AUTOSAR XML (schema 00044)
package /E40_Platform_System_SystemPackage/Components
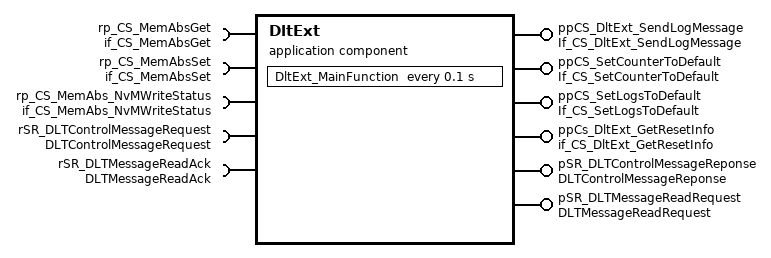
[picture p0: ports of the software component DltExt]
  application sw component type DltExt
    provide port ppCS_DltExt_SendLogMessage: server-com-spec{operation=SendLogMessage, queue-length=1}, provided-interface=If_CS_DltExt_SendLogMessage
    provide port ppCS_SetCounterToDefault: server-com-spec{operation=SetCounterToDefault, queue-length=1}, provided-interface=If_CS_SetCounterToDefault
    provide port ppCS_SetLogsToDefault: server-com-spec{operation=SetLogsToDefault, queue-length=1}, provided-interface=If_CS_SetLogsToDefault
    require port rp_CS_MemAbsGet: required-interface=if_CS_MemAbsGet
      required-com-specs:
        Get_BsConst_Audio_Element
        Get_BsConst_Communication_Element
        Get_BsConst_EngOffTimer_Element
        Get_BsConst_FuelGauge_Element
        Get_BsConst_OilGauge_Element
        Get_BsConst_PowerGauge_Element
        Get_BsConst_Power_Element
        Get_BsConst_RealTimeClock_Element
        Get_BsConst_ServiceReminder_Element
        Get_BsConst_SpeedoGauge_Element
        Get_BsConst_TachoGauge_Element
        Get_BsConst_TempGauge_Element
        Get_BsConst_TripComputer_Element
        Get_BsConst_Warning_Element
        Get_BsCys_Certicificate_Element
        Get_BsDiag_Dtc_Element
        Get_BsDiag_ErrorRecord_Element
        Get_BsReten_Audio_Element
        Get_BsReten_Communication_Element
        Get_BsReten_Display_Element
        Get_BsReten_Gauges_Element
        Get_BsReten_Illumination_Element
        Get_BsReten_Odometer_Element
        Get_BsReten_Personalization_Element
        Get_BsReten_Power_Element
        Get_BsReten_RealTimeClock_Element
        Get_BsReten_Tripcomputer_Element
        Get_BsReten_Warning_Element
        Get_BsRt_CusDlt_Element
        Get_BsRt_FuelGauge_Element
        Get_BsRt_Illumination_Element
        Get_BsRt_Odometer_Element
        Get_BsRt_OilGauge_Element
        Get_BsRt_Personalization_Element
        Get_BsRt_PowerGauge_Element
        Get_BsRt_RealTimeClock_Element
        Get_BsRt_SpeedoGauge_Element
        Get_BsRt_TachoGauge_Element
        Get_BsRt_TempGauge_Element
        Get_BsRt_TripComputer_Element
        Get_BsRt_Warning_Element
        Get_BsShare_EcuPartNumber_Element
        Get_BsShare_SwUpdFotaFinPrint_Element
        Get_BsShare_SwUpdFotaMode_Element
        Get_BsShare_SwUpdFotaStatus_Element
        Get_BsShare_SwUpdFotadecrypt_Element
        Get_BsShare_SwUpdReflash_Element
        Get_BsShare_VehicleConfig_Element
        Get_BsShare_VisMeet_Element
        Get_RefCys_Certicificate1_Element
        Get_RefCys_Certicificate_Element
        Get_BsShare_VisteonPartNumber
        Get_BsShare_VisteonPCBPartNumber
        Get_BsShare_SMTPlantNumber
        Get_BsShare_SMTManufacturingDate
        Get_BsShare_ProductSerialNumber
        Get_BsShare_PCBSerialNumber
        Get_BsShare_HWModification
        Get_BsShare_AssemblyPlantNumber
        Get_BsShare_AssemblyManufacturingDate
        Get_BsShare_VisMeet_EOLEntry_Element
        Get_BsConst_Temperature_Sensor_Conv_SafeCopy2
        Get_BsConst_Temperature_Sensor_Conv_SafeCopy1
        Get_BsConst_Temperature_Sensor_Conv
        Get_BsConst_Temp_Threshold_Hysteresis_Derating_SafeCopy2
        Get_BsConst_Temp_Threshold_Hysteresis_Derating_SafeCopy1
        Get_BsConst_Temp_Threshold_Hysteresis_Derating
        Get_BsConst_PWM_boost_bypass_duty_SafeCopy2
        Get_BsConst_PWM_boost_bypass_duty_SafeCopy1
        Get_BsConst_PWM_boost_bypass_duty
        Get_BsConst_PCB_Temperature_Sensor_Conv_SafeCopy2
        Get_BsConst_PCB_Temperature_Sensor_Conv_SafeCopy1
        Get_BsConst_PCB_Temperature_Sensor_Conv
        Get_BsConst_Lookup_Curve_HotSpot_Coef_Y_SafeCopy2
        Get_BsConst_Lookup_Curve_HotSpot_Coef_Y_SafeCopy1
        Get_BsConst_Lookup_Curve_HotSpot_Coef_Y
        Get_BsConst_Lookup_Curve_HotSpot_Coef_X_SafeCopy2
        Get_BsConst_Lookup_Curve_HotSpot_Coef_X_SafeCopy1
        Get_BsConst_Lookup_Curve_HotSpot_Coef_X
        Get_BsConst_Display_Illum_Max_Level_SafeCopy2
        Get_BsConst_Display_Illum_Max_Level_SafeCopy1
        Get_BsConst_Display_Illum_Max_Level
        Get_BsConst_Derating_Backlight_Disable_SafeCopy2
        Get_BsConst_Derating_Backlight_Disable_SafeCopy1
        Get_BsConst_Derating_Backlight_Disable
        Get_BsConst_Compensation_Line_Slope_m_SafeCopy2
        Get_BsConst_Compensation_Line_Slope_m_SafeCopy1
        Get_BsConst_Compensation_Line_Slope_m
        Get_BsConst_Compensation_Line_Shift_b_SafeCopy2
        Get_BsConst_Compensation_Line_Shift_b_SafeCopy1
        Get_BsConst_Compensation_Line_Shift_b
        Get_BsConst_BsConst_Illumination_ReservedByte_SafeCopy2
        Get_BsConst_BsConst_Illumination_ReservedByte_SafeCopy1
        Get_BsConst_BsConst_Illumination_ReservedByte
    require port rp_CS_MemAbsSet: required-interface=if_CS_MemAbsSet
      required-com-specs:
        Set_BsConst_Audio_Element
        Set_BsConst_Communication_Element
        Set_BsConst_EngOffTimer_Element
        Set_BsConst_FuelGauge_Element
        Set_BsConst_OilGauge_Element
        Set_BsConst_PowerGauge_Element
        Set_BsConst_Power_Element
        Set_BsConst_RealTimeClock_Element
        Set_BsConst_ServiceReminder_Element
        Set_BsConst_SpeedoGauge_Element
        Set_BsConst_TachoGauge_Element
        Set_BsConst_TempGauge_Element
        Set_BsConst_TripComputer_Element
        Set_BsConst_Warning_Element
        Set_BsCys_Certicificate_Element
        Set_BsDiag_Dtc_Element
        Set_BsDiag_ErrorRecord_Element
        Set_BsReten_Audio_Element
        Set_BsReten_Communication_Element
        Set_BsReten_Display_Element
        Set_BsReten_Gauges_Element
        Set_BsReten_Illumination_Element
        Set_BsReten_Odometer_Element
        Set_BsReten_Personalization_Element
        Set_BsReten_Power_Element
        Set_BsReten_RealTimeClock_Element
        Set_BsReten_Tripcomputer_Element
        Set_BsReten_Warning_Element
        Set_BsRt_CusDlt_Element
        Set_BsRt_FuelGauge_Element
        Set_BsRt_Illumination_Element
        Set_BsRt_Odometer_Element
        Set_BsRt_OilGauge_Element
        Set_BsRt_Personalization_Element
        Set_BsRt_PowerGauge_Element
        Set_BsRt_RealTimeClock_Element
        Set_BsRt_SpeedoGauge_Element
        Set_BsRt_TachoGauge_Element
        Set_BsRt_TempGauge_Element
        Set_BsRt_TripComputer_Element
        Set_BsRt_Warning_Element
        Set_BsShare_EcuPartNumber_Element
        Set_BsShare_SwUpdFotaFinPrint_Element
        Set_BsShare_SwUpdFotaMode_Element
        Set_BsShare_SwUpdFotaStatus_Element
        Set_BsShare_SwUpdFotadecrypt_Element
        Set_BsShare_SwUpdReflash_Element
        Set_BsShare_VehicleConfig_Element
        Set_BsShare_VisMeet_Element
        Set_RefCys_Certicificate1_Element
        Set_RefCys_Certicificate_Element
        Set_BsShare_VisteonPartNumber
        Set_BsShare_VisteonPCBPartNumber
        Set_BsShare_SMTPlantNumber
        Set_BsShare_SMTManufacturingDate
        Set_BsShare_ProductSerialNumber
        Set_BsShare_PCBSerialNumber
        Set_BsShare_HWModification
        Set_BsShare_AssemblyPlantNumber
        Set_BsShare_AssemblyManufacturingDate
        Set_BsShare_VisMeet_EOLEntry_Element
        Set_BsConst_Temperature_Sensor_Conv_SafeCopy2
        Set_BsConst_Temperature_Sensor_Conv_SafeCopy1
        Set_BsConst_Temperature_Sensor_Conv
        Set_BsConst_Temp_Threshold_Hysteresis_Derating_SafeCopy2
        Set_BsConst_Temp_Threshold_Hysteresis_Derating_SafeCopy1
        Set_BsConst_Temp_Threshold_Hysteresis_Derating
        Set_BsConst_PWM_boost_bypass_duty_SafeCopy2
        Set_BsConst_PWM_boost_bypass_duty_SafeCopy1
        Set_BsConst_PWM_boost_bypass_duty
        Set_BsConst_PCB_Temperature_Sensor_Conv_SafeCopy2
        Set_BsConst_PCB_Temperature_Sensor_Conv_SafeCopy1
        Set_BsConst_PCB_Temperature_Sensor_Conv
        Set_BsConst_Lookup_Curve_HotSpot_Coef_Y_SafeCopy2
        Set_BsConst_Lookup_Curve_HotSpot_Coef_Y_SafeCopy1
        Set_BsConst_Lookup_Curve_HotSpot_Coef_Y
        Set_BsConst_Lookup_Curve_HotSpot_Coef_X_SafeCopy2
        Set_BsConst_Lookup_Curve_HotSpot_Coef_X_SafeCopy1
        Set_BsConst_Lookup_Curve_HotSpot_Coef_X
        Set_BsConst_Display_Illum_Max_Level_SafeCopy2
        Set_BsConst_Display_Illum_Max_Level_SafeCopy1
        Set_BsConst_Display_Illum_Max_Level
        Set_BsConst_Derating_Backlight_Disable_SafeCopy2
        Set_BsConst_Derating_Backlight_Disable_SafeCopy1
        Set_BsConst_Derating_Backlight_Disable
        Set_BsConst_Compensation_Line_Slope_m_SafeCopy2
        Set_BsConst_Compensation_Line_Slope_m_SafeCopy1
        Set_BsConst_Compensation_Line_Slope_m
        Set_BsConst_Compensation_Line_Shift_b_SafeCopy2
        Set_BsConst_Compensation_Line_Shift_b_SafeCopy1
        Set_BsConst_Compensation_Line_Shift_b
        Set_BsConst_BsConst_Illumination_ReservedByte_SafeCopy2
        Set_BsConst_BsConst_Illumination_ReservedByte_SafeCopy1
        Set_BsConst_BsConst_Illumination_ReservedByte
    require port rp_CS_MemAbs_NvMWriteStatus: client-com-spec=NvmWriteStatus, required-interface=if_CS_MemAbs_NvMWriteStatus
    provide port ppCs_DltExt_GetResetInfo: server-com-spec{operation=GetResetInfo, queue-length=1}, provided-interface=if_CS_DltExt_GetResetInfo
    provide port pSR_DLTControlMessageReponse: nonqueued-sender-com-spec{data-element=DLTControlMessageReponseData, init-value=constant-reference=DltExtDLTControlMessageReponseDataValue0}, provided-interface=DLTControlMessageReponse
    provide port pSR_DLTMessageReadRequest: nonqueued-sender-com-spec{data-element=DLTMessageReadRequestData, init-value=constant-reference=DltExtDLTMessageReadRequestDataValue0}, provided-interface=DLTMessageReadRequest
    require port rSR_DLTControlMessageRequest: nonqueued-receiver-com-spec{data-element=DLTControlMessageRequestData, init-value=constant-reference=DltExtDLTControlMessageRequestDataValue0}, required-interface=DLTControlMessageRequest
    require port rSR_DLTMessageReadAck: nonqueued-receiver-com-spec{data-element=DLTMessageReadAckData, init-value=constant-reference=DltExtDLTMessageReadAckDataValue0}, required-interface=DLTMessageReadAck
    behavior IB_DltExt
      timing event TEDltExt_MainFunction: start-on-event=DltExt_MainFunction, period=0.1
      4 x operation invoked event:
        OIE_ppCS_DltExt_SendLogMessage_DltExt_SendLogMessageTrigBySendLogMessage: start-on-event=DltExt_SendLogMessage, operation=ppCS_DltExt_SendLogMessage.SendLogMessage
        OIE_ppCS_SetCounterToDefault_DltExt_SetCounterToDefaultTrigBySetCounterToDefault: start-on-event=DltExt_SetCounterToDefault, operation=ppCS_SetCounterToDefault.SetCounterToDefault
        OIE_ppCS_SetLogsToDefault_DltExt_SetLogsToDefaultTrigBySetLogsToDefault: start-on-event=DltExt_SetLogsToDefault, operation=ppCS_SetLogsToDefault.SetLogsToDefault
        OIE_ppCs_DltExt_GetResetInfo_DltExt_GetResetInfoTrigByGetResetInfo: start-on-event=DltExt_GetResetInfo, operation=ppCs_DltExt_GetResetInfo.GetResetInfo
      data received event DREDltExt_OnDreDLTMessageReadAckDataTrigByDLTMessageReadAckData: start-on-event=DltExt_OnDreDLTMessageReadAckData, data=rSR_DLTMessageReadAck.DLTMessageReadAckData
      port-api-options:
        enable-take-address=false, indirect-api=false, port=ppCS_DltExt_SendLogMessage
        enable-take-address=false, indirect-api=false, port=ppCS_SetCounterToDefault
        enable-take-address=false, indirect-api=false, port=ppCS_SetLogsToDefault
        enable-take-address=false, indirect-api=false, port=rp_CS_MemAbsGet
        enable-take-address=false, indirect-api=false, port=rp_CS_MemAbsSet
        enable-take-address=false, indirect-api=false, port=rp_CS_MemAbs_NvMWriteStatus
        enable-take-address=false, indirect-api=false, port=ppCs_DltExt_GetResetInfo
        enable-take-address=false, indirect-api=false, port=pSR_DLTControlMessageReponse
        enable-take-address=false, indirect-api=false, port=pSR_DLTMessageReadRequest
        enable-take-address=false, indirect-api=false, port=rSR_DLTControlMessageRequest
        enable-take-address=false, indirect-api=false, port=rSR_DLTMessageReadAck
      6 x runnable, all with can-be-invoked-concurrently=true:
        DltExt_MainFunction
          data-receive-point-by-arguments:
            access DRA_rSR_DLTControlMessageRequest_DLTControlMessageRequestData: accessed-variable=rSR_DLTControlMessageRequest.DLTControlMessageRequestData
            access DRA_rSR_DLTMessageReadAck_DLTMessageReadAckData: accessed-variable=rSR_DLTMessageReadAck.DLTMessageReadAckData
          data-send-points:
            access DWA_pSR_DLTControlMessageReponse_DLTControlMessageReponseData: accessed-variable=pSR_DLTControlMessageReponse.DLTControlMessageReponseData
            access DWA_pSR_DLTMessageReadRequest_DLTMessageReadRequestData: accessed-variable=pSR_DLTMessageReadRequest.DLTMessageReadRequestData
          189 x sync call:
            OA_rp_CS_MemAbsGet_Get_BsShare_SwUpdReflash_Element: operation=rp_CS_MemAbsGet.Get_BsShare_SwUpdReflash_Element
            OA_rp_CS_MemAbsGet_Get_BsShare_SwUpdFotaMode_Element: operation=rp_CS_MemAbsGet.Get_BsShare_SwUpdFotaMode_Element
            OA_rp_CS_MemAbsGet_Get_BsShare_SwUpdFotaFinPrint_Element: operation=rp_CS_MemAbsGet.Get_BsShare_SwUpdFotaFinPrint_Element
            OA_rp_CS_MemAbsGet_Get_BsShare_SwUpdFotaStatus_Element: operation=rp_CS_MemAbsGet.Get_BsShare_SwUpdFotaStatus_Element
            OA_rp_CS_MemAbsGet_Get_BsShare_SwUpdFotadecrypt_Element: operation=rp_CS_MemAbsGet.Get_BsShare_SwUpdFotadecrypt_Element
            OA_rp_CS_MemAbsGet_Get_BsShare_EcuPartNumber_Element: operation=rp_CS_MemAbsGet.Get_BsShare_EcuPartNumber_Element
            OA_rp_CS_MemAbsGet_Get_BsShare_VisMeet_Element: operation=rp_CS_MemAbsGet.Get_BsShare_VisMeet_Element
            OA_rp_CS_MemAbsGet_Get_BsShare_VehicleConfig_Element: operation=rp_CS_MemAbsGet.Get_BsShare_VehicleConfig_Element
            OA_rp_CS_MemAbsGet_Get_BsConst_SpeedoGauge_Element: operation=rp_CS_MemAbsGet.Get_BsConst_SpeedoGauge_Element
            OA_rp_CS_MemAbsGet_Get_BsConst_TachoGauge_Element: operation=rp_CS_MemAbsGet.Get_BsConst_TachoGauge_Element
            OA_rp_CS_MemAbsGet_Get_BsConst_FuelGauge_Element: operation=rp_CS_MemAbsGet.Get_BsConst_FuelGauge_Element
            OA_rp_CS_MemAbsGet_Get_BsConst_TempGauge_Element: operation=rp_CS_MemAbsGet.Get_BsConst_TempGauge_Element
            OA_rp_CS_MemAbsGet_Get_BsConst_PowerGauge_Element: operation=rp_CS_MemAbsGet.Get_BsConst_PowerGauge_Element
            OA_rp_CS_MemAbsGet_Get_BsConst_OilGauge_Element: operation=rp_CS_MemAbsGet.Get_BsConst_OilGauge_Element
            OA_rp_CS_MemAbsGet_Get_BsConst_TripComputer_Element: operation=rp_CS_MemAbsGet.Get_BsConst_TripComputer_Element
            OA_rp_CS_MemAbsGet_Get_BsConst_Audio_Element: operation=rp_CS_MemAbsGet.Get_BsConst_Audio_Element
            OA_rp_CS_MemAbsGet_Get_BsConst_Warning_Element: operation=rp_CS_MemAbsGet.Get_BsConst_Warning_Element
            OA_rp_CS_MemAbsGet_Get_BsConst_RealTimeClock_Element: operation=rp_CS_MemAbsGet.Get_BsConst_RealTimeClock_Element
            OA_rp_CS_MemAbsGet_Get_BsConst_Communication_Element: operation=rp_CS_MemAbsGet.Get_BsConst_Communication_Element
            OA_rp_CS_MemAbsGet_Get_BsConst_Power_Element: operation=rp_CS_MemAbsGet.Get_BsConst_Power_Element
            OA_rp_CS_MemAbsGet_Get_BsConst_ServiceReminder_Element: operation=rp_CS_MemAbsGet.Get_BsConst_ServiceReminder_Element
            OA_rp_CS_MemAbsGet_Get_BsConst_EngOffTimer_Element: operation=rp_CS_MemAbsGet.Get_BsConst_EngOffTimer_Element
            OA_rp_CS_MemAbsGet_Get_BsCys_Certicificate_Element: operation=rp_CS_MemAbsGet.Get_BsCys_Certicificate_Element
            OA_rp_CS_MemAbsGet_Get_RefCys_Certicificate_Element: operation=rp_CS_MemAbsGet.Get_RefCys_Certicificate_Element
            OA_rp_CS_MemAbsGet_Get_RefCys_Certicificate1_Element: operation=rp_CS_MemAbsGet.Get_RefCys_Certicificate1_Element
            OA_rp_CS_MemAbsGet_Get_BsRt_Odometer_Element: operation=rp_CS_MemAbsGet.Get_BsRt_Odometer_Element
            OA_rp_CS_MemAbsGet_Get_BsRt_SpeedoGauge_Element: operation=rp_CS_MemAbsGet.Get_BsRt_SpeedoGauge_Element
            OA_rp_CS_MemAbsGet_Get_BsRt_TachoGauge_Element: operation=rp_CS_MemAbsGet.Get_BsRt_TachoGauge_Element
            OA_rp_CS_MemAbsGet_Get_BsRt_FuelGauge_Element: operation=rp_CS_MemAbsGet.Get_BsRt_FuelGauge_Element
            OA_rp_CS_MemAbsGet_Get_BsRt_TempGauge_Element: operation=rp_CS_MemAbsGet.Get_BsRt_TempGauge_Element
            OA_rp_CS_MemAbsGet_Get_BsRt_PowerGauge_Element: operation=rp_CS_MemAbsGet.Get_BsRt_PowerGauge_Element
            OA_rp_CS_MemAbsGet_Get_BsRt_OilGauge_Element: operation=rp_CS_MemAbsGet.Get_BsRt_OilGauge_Element
            OA_rp_CS_MemAbsGet_Get_BsRt_TripComputer_Element: operation=rp_CS_MemAbsGet.Get_BsRt_TripComputer_Element
            OA_rp_CS_MemAbsGet_Get_BsRt_Warning_Element: operation=rp_CS_MemAbsGet.Get_BsRt_Warning_Element
            OA_rp_CS_MemAbsGet_Get_BsRt_RealTimeClock_Element: operation=rp_CS_MemAbsGet.Get_BsRt_RealTimeClock_Element
            OA_rp_CS_MemAbsGet_Get_BsRt_Personalization_Element: operation=rp_CS_MemAbsGet.Get_BsRt_Personalization_Element
            OA_rp_CS_MemAbsGet_Get_BsRt_Illumination_Element: operation=rp_CS_MemAbsGet.Get_BsRt_Illumination_Element
            OA_rp_CS_MemAbsGet_Get_BsRt_CusDlt_Element: operation=rp_CS_MemAbsGet.Get_BsRt_CusDlt_Element
            OA_rp_CS_MemAbsGet_Get_BsReten_Odometer_Element: operation=rp_CS_MemAbsGet.Get_BsReten_Odometer_Element
            OA_rp_CS_MemAbsGet_Get_BsReten_Gauges_Element: operation=rp_CS_MemAbsGet.Get_BsReten_Gauges_Element
            OA_rp_CS_MemAbsGet_Get_BsReten_Tripcomputer_Element: operation=rp_CS_MemAbsGet.Get_BsReten_Tripcomputer_Element
            OA_rp_CS_MemAbsGet_Get_BsReten_Illumination_Element: operation=rp_CS_MemAbsGet.Get_BsReten_Illumination_Element
            OA_rp_CS_MemAbsGet_Get_BsReten_Audio_Element: operation=rp_CS_MemAbsGet.Get_BsReten_Audio_Element
            OA_rp_CS_MemAbsGet_Get_BsReten_Warning_Element: operation=rp_CS_MemAbsGet.Get_BsReten_Warning_Element
            OA_rp_CS_MemAbsGet_Get_BsReten_RealTimeClock_Element: operation=rp_CS_MemAbsGet.Get_BsReten_RealTimeClock_Element
            OA_rp_CS_MemAbsGet_Get_BsReten_Communication_Element: operation=rp_CS_MemAbsGet.Get_BsReten_Communication_Element
            OA_rp_CS_MemAbsGet_Get_BsReten_Personalization_Element: operation=rp_CS_MemAbsGet.Get_BsReten_Personalization_Element
            OA_rp_CS_MemAbsGet_Get_BsReten_Power_Element: operation=rp_CS_MemAbsGet.Get_BsReten_Power_Element
            OA_rp_CS_MemAbsGet_Get_BsReten_Display_Element: operation=rp_CS_MemAbsGet.Get_BsReten_Display_Element
            OA_rp_CS_MemAbsGet_Get_BsDiag_ErrorRecord_Element: operation=rp_CS_MemAbsGet.Get_BsDiag_ErrorRecord_Element
            OA_rp_CS_MemAbsGet_Get_BsDiag_Dtc_Element: operation=rp_CS_MemAbsGet.Get_BsDiag_Dtc_Element
            OA_rp_CS_MemAbsSet_Set_BsShare_SwUpdReflash_Element: operation=rp_CS_MemAbsSet.Set_BsShare_SwUpdReflash_Element
            OA_rp_CS_MemAbsSet_Set_BsShare_SwUpdFotaMode_Element: operation=rp_CS_MemAbsSet.Set_BsShare_SwUpdFotaMode_Element
            OA_rp_CS_MemAbsSet_Set_BsShare_SwUpdFotaFinPrint_Element: operation=rp_CS_MemAbsSet.Set_BsShare_SwUpdFotaFinPrint_Element
            OA_rp_CS_MemAbsSet_Set_BsShare_SwUpdFotaStatus_Element: operation=rp_CS_MemAbsSet.Set_BsShare_SwUpdFotaStatus_Element
            OA_rp_CS_MemAbsSet_Set_BsShare_SwUpdFotadecrypt_Element: operation=rp_CS_MemAbsSet.Set_BsShare_SwUpdFotadecrypt_Element
            OA_rp_CS_MemAbsSet_Set_BsShare_EcuPartNumber_Element: operation=rp_CS_MemAbsSet.Set_BsShare_EcuPartNumber_Element
            OA_rp_CS_MemAbsSet_Set_BsShare_VisMeet_Element: operation=rp_CS_MemAbsSet.Set_BsShare_VisMeet_Element
            OA_rp_CS_MemAbsSet_Set_BsShare_VehicleConfig_Element: operation=rp_CS_MemAbsSet.Set_BsShare_VehicleConfig_Element
            OA_rp_CS_MemAbsSet_Set_BsConst_SpeedoGauge_Element: operation=rp_CS_MemAbsSet.Set_BsConst_SpeedoGauge_Element
            OA_rp_CS_MemAbsSet_Set_BsConst_TachoGauge_Element: operation=rp_CS_MemAbsSet.Set_BsConst_TachoGauge_Element
            OA_rp_CS_MemAbsSet_Set_BsConst_FuelGauge_Element: operation=rp_CS_MemAbsSet.Set_BsConst_FuelGauge_Element
            OA_rp_CS_MemAbsSet_Set_BsConst_TempGauge_Element: operation=rp_CS_MemAbsSet.Set_BsConst_TempGauge_Element
            OA_rp_CS_MemAbsSet_Set_BsConst_PowerGauge_Element: operation=rp_CS_MemAbsSet.Set_BsConst_PowerGauge_Element
            OA_rp_CS_MemAbsSet_Set_BsConst_OilGauge_Element: operation=rp_CS_MemAbsSet.Set_BsConst_OilGauge_Element
            OA_rp_CS_MemAbsSet_Set_BsConst_TripComputer_Element: operation=rp_CS_MemAbsSet.Set_BsConst_TripComputer_Element
            OA_rp_CS_MemAbsSet_Set_BsConst_Audio_Element: operation=rp_CS_MemAbsSet.Set_BsConst_Audio_Element
            OA_rp_CS_MemAbsSet_Set_BsConst_Warning_Element: operation=rp_CS_MemAbsSet.Set_BsConst_Warning_Element
            OA_rp_CS_MemAbsSet_Set_BsConst_RealTimeClock_Element: operation=rp_CS_MemAbsSet.Set_BsConst_RealTimeClock_Element
            OA_rp_CS_MemAbsSet_Set_BsConst_Communication_Element: operation=rp_CS_MemAbsSet.Set_BsConst_Communication_Element
            OA_rp_CS_MemAbsSet_Set_BsConst_Power_Element: operation=rp_CS_MemAbsSet.Set_BsConst_Power_Element
            OA_rp_CS_MemAbsSet_Set_BsConst_ServiceReminder_Element: operation=rp_CS_MemAbsSet.Set_BsConst_ServiceReminder_Element
            OA_rp_CS_MemAbsSet_Set_BsConst_EngOffTimer_Element: operation=rp_CS_MemAbsSet.Set_BsConst_EngOffTimer_Element
            OA_rp_CS_MemAbsSet_Set_BsCys_Certicificate_Element: operation=rp_CS_MemAbsSet.Set_BsCys_Certicificate_Element
            OA_rp_CS_MemAbsSet_Set_RefCys_Certicificate_Element: operation=rp_CS_MemAbsSet.Set_RefCys_Certicificate_Element
            OA_rp_CS_MemAbsSet_Set_RefCys_Certicificate1_Element: operation=rp_CS_MemAbsSet.Set_RefCys_Certicificate1_Element
            OA_rp_CS_MemAbsSet_Set_BsRt_Odometer_Element: operation=rp_CS_MemAbsSet.Set_BsRt_Odometer_Element
            OA_rp_CS_MemAbsSet_Set_BsRt_SpeedoGauge_Element: operation=rp_CS_MemAbsSet.Set_BsRt_SpeedoGauge_Element
            OA_rp_CS_MemAbsSet_Set_BsRt_TachoGauge_Element: operation=rp_CS_MemAbsSet.Set_BsRt_TachoGauge_Element
            OA_rp_CS_MemAbsSet_Set_BsRt_FuelGauge_Element: operation=rp_CS_MemAbsSet.Set_BsRt_FuelGauge_Element
            OA_rp_CS_MemAbsSet_Set_BsRt_TempGauge_Element: operation=rp_CS_MemAbsSet.Set_BsRt_TempGauge_Element
            OA_rp_CS_MemAbsSet_Set_BsRt_PowerGauge_Element: operation=rp_CS_MemAbsSet.Set_BsRt_PowerGauge_Element
            OA_rp_CS_MemAbsSet_Set_BsRt_OilGauge_Element: operation=rp_CS_MemAbsSet.Set_BsRt_OilGauge_Element
            OA_rp_CS_MemAbsSet_Set_BsRt_TripComputer_Element: operation=rp_CS_MemAbsSet.Set_BsRt_TripComputer_Element
            OA_rp_CS_MemAbsSet_Set_BsRt_Warning_Element: operation=rp_CS_MemAbsSet.Set_BsRt_Warning_Element
            OA_rp_CS_MemAbsSet_Set_BsRt_RealTimeClock_Element: operation=rp_CS_MemAbsSet.Set_BsRt_RealTimeClock_Element
            OA_rp_CS_MemAbsSet_Set_BsRt_Personalization_Element: operation=rp_CS_MemAbsSet.Set_BsRt_Personalization_Element
            OA_rp_CS_MemAbsSet_Set_BsRt_Illumination_Element: operation=rp_CS_MemAbsSet.Set_BsRt_Illumination_Element
            OA_rp_CS_MemAbsSet_Set_BsRt_CusDlt_Element: operation=rp_CS_MemAbsSet.Set_BsRt_CusDlt_Element
            OA_rp_CS_MemAbsSet_Set_BsReten_Odometer_Element: operation=rp_CS_MemAbsSet.Set_BsReten_Odometer_Element
            OA_rp_CS_MemAbsSet_Set_BsReten_Gauges_Element: operation=rp_CS_MemAbsSet.Set_BsReten_Gauges_Element
            OA_rp_CS_MemAbsSet_Set_BsReten_Tripcomputer_Element: operation=rp_CS_MemAbsSet.Set_BsReten_Tripcomputer_Element
            OA_rp_CS_MemAbsSet_Set_BsReten_Illumination_Element: operation=rp_CS_MemAbsSet.Set_BsReten_Illumination_Element
            OA_rp_CS_MemAbsSet_Set_BsReten_Audio_Element: operation=rp_CS_MemAbsSet.Set_BsReten_Audio_Element
            OA_rp_CS_MemAbsSet_Set_BsReten_Warning_Element: operation=rp_CS_MemAbsSet.Set_BsReten_Warning_Element
            OA_rp_CS_MemAbsSet_Set_BsReten_RealTimeClock_Element: operation=rp_CS_MemAbsSet.Set_BsReten_RealTimeClock_Element
            OA_rp_CS_MemAbsSet_Set_BsReten_Communication_Element: operation=rp_CS_MemAbsSet.Set_BsReten_Communication_Element
            OA_rp_CS_MemAbsSet_Set_BsReten_Personalization_Element: operation=rp_CS_MemAbsSet.Set_BsReten_Personalization_Element
            OA_rp_CS_MemAbsSet_Set_BsReten_Power_Element: operation=rp_CS_MemAbsSet.Set_BsReten_Power_Element
            OA_rp_CS_MemAbsSet_Set_BsReten_Display_Element: operation=rp_CS_MemAbsSet.Set_BsReten_Display_Element
            OA_rp_CS_MemAbsSet_Set_BsDiag_ErrorRecord_Element: operation=rp_CS_MemAbsSet.Set_BsDiag_ErrorRecord_Element
            OA_rp_CS_MemAbsSet_Set_BsDiag_Dtc_Element: operation=rp_CS_MemAbsSet.Set_BsDiag_Dtc_Element
            OA_rp_CS_MemAbs_NvMWriteStatus_NvmWriteStatus: operation=rp_CS_MemAbs_NvMWriteStatus.NvmWriteStatus
            OA_rp_CS_MemAbsGet_Get_BsShare_VisteonPartNumber: operation=rp_CS_MemAbsGet.Get_BsShare_VisteonPartNumber
            OA_rp_CS_MemAbsGet_Get_BsShare_VisteonPCBPartNumber: operation=rp_CS_MemAbsGet.Get_BsShare_VisteonPCBPartNumber
            OA_rp_CS_MemAbsGet_Get_BsShare_ProductSerialNumber: operation=rp_CS_MemAbsGet.Get_BsShare_ProductSerialNumber
            OA_rp_CS_MemAbsGet_Get_BsShare_PCBSerialNumber: operation=rp_CS_MemAbsGet.Get_BsShare_PCBSerialNumber
            OA_rp_CS_MemAbsGet_Get_BsShare_SMTManufacturingDate: operation=rp_CS_MemAbsGet.Get_BsShare_SMTManufacturingDate
            OA_rp_CS_MemAbsGet_Get_BsShare_AssemblyManufacturingDate: operation=rp_CS_MemAbsGet.Get_BsShare_AssemblyManufacturingDate
            OA_rp_CS_MemAbsGet_Get_BsShare_SMTPlantNumber: operation=rp_CS_MemAbsGet.Get_BsShare_SMTPlantNumber
            OA_rp_CS_MemAbsGet_Get_BsShare_AssemblyPlantNumber: operation=rp_CS_MemAbsGet.Get_BsShare_AssemblyPlantNumber
            OA_rp_CS_MemAbsGet_Get_BsShare_HWModification: operation=rp_CS_MemAbsGet.Get_BsShare_HWModification
            OA_rp_CS_MemAbsGet_Get_BsShare_VisMeet_EOLEntry_Element: operation=rp_CS_MemAbsGet.Get_BsShare_VisMeet_EOLEntry_Element
            OA_rp_CS_MemAbsSet_Set_BsShare_VisteonPartNumber: operation=rp_CS_MemAbsSet.Set_BsShare_VisteonPartNumber
            OA_rp_CS_MemAbsSet_Set_BsShare_VisteonPCBPartNumber: operation=rp_CS_MemAbsSet.Set_BsShare_VisteonPCBPartNumber
            OA_rp_CS_MemAbsSet_Set_BsShare_ProductSerialNumber: operation=rp_CS_MemAbsSet.Set_BsShare_ProductSerialNumber
            OA_rp_CS_MemAbsSet_Set_BsShare_PCBSerialNumber: operation=rp_CS_MemAbsSet.Set_BsShare_PCBSerialNumber
            OA_rp_CS_MemAbsSet_Set_BsShare_SMTManufacturingDate: operation=rp_CS_MemAbsSet.Set_BsShare_SMTManufacturingDate
            OA_rp_CS_MemAbsSet_Set_BsShare_AssemblyManufacturingDate: operation=rp_CS_MemAbsSet.Set_BsShare_AssemblyManufacturingDate
            OA_rp_CS_MemAbsSet_Set_BsShare_SMTPlantNumber: operation=rp_CS_MemAbsSet.Set_BsShare_SMTPlantNumber
            OA_rp_CS_MemAbsSet_Set_BsShare_AssemblyPlantNumber: operation=rp_CS_MemAbsSet.Set_BsShare_AssemblyPlantNumber
            OA_rp_CS_MemAbsSet_Set_BsShare_HWModification: operation=rp_CS_MemAbsSet.Set_BsShare_HWModification
            OA_rp_CS_MemAbsSet_Set_BsShare_VisMeet_EOLEntry_Element: operation=rp_CS_MemAbsSet.Set_BsShare_VisMeet_EOLEntry_Element
            OA_rp_CS_MemAbsGet_Get_BsConst_Compensation_Line_Slope_m: operation=rp_CS_MemAbsGet.Get_BsConst_Compensation_Line_Slope_m
            OA_rp_CS_MemAbsGet_Get_BsConst_Compensation_Line_Shift_b: operation=rp_CS_MemAbsGet.Get_BsConst_Compensation_Line_Shift_b
            OA_rp_CS_MemAbsGet_Get_BsConst_Lookup_Curve_HotSpot_Coef_X: operation=rp_CS_MemAbsGet.Get_BsConst_Lookup_Curve_HotSpot_Coef_X
            OA_rp_CS_MemAbsGet_Get_BsConst_Lookup_Curve_HotSpot_Coef_Y: operation=rp_CS_MemAbsGet.Get_BsConst_Lookup_Curve_HotSpot_Coef_Y
            OA_rp_CS_MemAbsGet_Get_BsConst_Temp_Threshold_Hysteresis_Derating: operation=rp_CS_MemAbsGet.Get_BsConst_Temp_Threshold_Hysteresis_Derating
            OA_rp_CS_MemAbsGet_Get_BsConst_Derating_Backlight_Disable: operation=rp_CS_MemAbsGet.Get_BsConst_Derating_Backlight_Disable
            OA_rp_CS_MemAbsGet_Get_BsConst_Temperature_Sensor_Conv: operation=rp_CS_MemAbsGet.Get_BsConst_Temperature_Sensor_Conv
            OA_rp_CS_MemAbsGet_Get_BsConst_PCB_Temperature_Sensor_Conv: operation=rp_CS_MemAbsGet.Get_BsConst_PCB_Temperature_Sensor_Conv
            OA_rp_CS_MemAbsGet_Get_BsConst_Display_Illum_Max_Level: operation=rp_CS_MemAbsGet.Get_BsConst_Display_Illum_Max_Level
            OA_rp_CS_MemAbsGet_Get_BsConst_PWM_boost_bypass_duty: operation=rp_CS_MemAbsGet.Get_BsConst_PWM_boost_bypass_duty
            OA_rp_CS_MemAbsGet_Get_BsConst_BsConst_Illumination_ReservedByte: operation=rp_CS_MemAbsGet.Get_BsConst_BsConst_Illumination_ReservedByte
            OA_rp_CS_MemAbsGet_Get_BsConst_Compensation_Line_Slope_m_SafeCopy1: operation=rp_CS_MemAbsGet.Get_BsConst_Compensation_Line_Slope_m_SafeCopy1
            OA_rp_CS_MemAbsGet_Get_BsConst_Compensation_Line_Shift_b_SafeCopy1: operation=rp_CS_MemAbsGet.Get_BsConst_Compensation_Line_Shift_b_SafeCopy1
            OA_rp_CS_MemAbsGet_Get_BsConst_Lookup_Curve_HotSpot_Coef_X_SafeCopy1: operation=rp_CS_MemAbsGet.Get_BsConst_Lookup_Curve_HotSpot_Coef_X_SafeCopy1
            OA_rp_CS_MemAbsGet_Get_BsConst_Lookup_Curve_HotSpot_Coef_Y_SafeCopy1: operation=rp_CS_MemAbsGet.Get_BsConst_Lookup_Curve_HotSpot_Coef_Y_SafeCopy1
            OA_rp_CS_MemAbsGet_Get_BsConst_Temp_Threshold_Hysteresis_Derating_SafeCopy1: operation=rp_CS_MemAbsGet.Get_BsConst_Temp_Threshold_Hysteresis_Derating_SafeCopy1
            OA_rp_CS_MemAbsGet_Get_BsConst_Derating_Backlight_Disable_SafeCopy1: operation=rp_CS_MemAbsGet.Get_BsConst_Derating_Backlight_Disable_SafeCopy1
            OA_rp_CS_MemAbsGet_Get_BsConst_Temperature_Sensor_Conv_SafeCopy1: operation=rp_CS_MemAbsGet.Get_BsConst_Temperature_Sensor_Conv_SafeCopy1
            OA_rp_CS_MemAbsGet_Get_BsConst_PCB_Temperature_Sensor_Conv_SafeCopy1: operation=rp_CS_MemAbsGet.Get_BsConst_PCB_Temperature_Sensor_Conv_SafeCopy1
            OA_rp_CS_MemAbsGet_Get_BsConst_Display_Illum_Max_Level_SafeCopy1: operation=rp_CS_MemAbsGet.Get_BsConst_Display_Illum_Max_Level_SafeCopy1
            OA_rp_CS_MemAbsGet_Get_BsConst_PWM_boost_bypass_duty_SafeCopy1: operation=rp_CS_MemAbsGet.Get_BsConst_PWM_boost_bypass_duty_SafeCopy1
            OA_rp_CS_MemAbsGet_Get_BsConst_BsConst_Illumination_ReservedByte_SafeCopy1: operation=rp_CS_MemAbsGet.Get_BsConst_BsConst_Illumination_ReservedByte_SafeCopy1
            OA_rp_CS_MemAbsGet_Get_BsConst_Compensation_Line_Slope_m_SafeCopy2: operation=rp_CS_MemAbsGet.Get_BsConst_Compensation_Line_Slope_m_SafeCopy2
            OA_rp_CS_MemAbsGet_Get_BsConst_Compensation_Line_Shift_b_SafeCopy2: operation=rp_CS_MemAbsGet.Get_BsConst_Compensation_Line_Shift_b_SafeCopy2
            OA_rp_CS_MemAbsGet_Get_BsConst_Lookup_Curve_HotSpot_Coef_X_SafeCopy2: operation=rp_CS_MemAbsGet.Get_BsConst_Lookup_Curve_HotSpot_Coef_X_SafeCopy2
            OA_rp_CS_MemAbsGet_Get_BsConst_Lookup_Curve_HotSpot_Coef_Y_SafeCopy2: operation=rp_CS_MemAbsGet.Get_BsConst_Lookup_Curve_HotSpot_Coef_Y_SafeCopy2
            OA_rp_CS_MemAbsGet_Get_BsConst_Temp_Threshold_Hysteresis_Derating_SafeCopy2: operation=rp_CS_MemAbsGet.Get_BsConst_Temp_Threshold_Hysteresis_Derating_SafeCopy2
            OA_rp_CS_MemAbsGet_Get_BsConst_Derating_Backlight_Disable_SafeCopy2: operation=rp_CS_MemAbsGet.Get_BsConst_Derating_Backlight_Disable_SafeCopy2
            OA_rp_CS_MemAbsGet_Get_BsConst_Temperature_Sensor_Conv_SafeCopy2: operation=rp_CS_MemAbsGet.Get_BsConst_Temperature_Sensor_Conv_SafeCopy2
            OA_rp_CS_MemAbsGet_Get_BsConst_PCB_Temperature_Sensor_Conv_SafeCopy2: operation=rp_CS_MemAbsGet.Get_BsConst_PCB_Temperature_Sensor_Conv_SafeCopy2
            OA_rp_CS_MemAbsGet_Get_BsConst_Display_Illum_Max_Level_SafeCopy2: operation=rp_CS_MemAbsGet.Get_BsConst_Display_Illum_Max_Level_SafeCopy2
            OA_rp_CS_MemAbsGet_Get_BsConst_PWM_boost_bypass_duty_SafeCopy2: operation=rp_CS_MemAbsGet.Get_BsConst_PWM_boost_bypass_duty_SafeCopy2
            OA_rp_CS_MemAbsGet_Get_BsConst_BsConst_Illumination_ReservedByte_SafeCopy2: operation=rp_CS_MemAbsGet.Get_BsConst_BsConst_Illumination_ReservedByte_SafeCopy2
            OA_rp_CS_MemAbsSet_Set_BsConst_Compensation_Line_Slope_m: operation=rp_CS_MemAbsSet.Set_BsConst_Compensation_Line_Slope_m
            OA_rp_CS_MemAbsSet_Set_BsConst_Compensation_Line_Shift_b: operation=rp_CS_MemAbsSet.Set_BsConst_Compensation_Line_Shift_b
            OA_rp_CS_MemAbsSet_Set_BsConst_Lookup_Curve_HotSpot_Coef_X: operation=rp_CS_MemAbsSet.Set_BsConst_Lookup_Curve_HotSpot_Coef_X
            OA_rp_CS_MemAbsSet_Set_BsConst_Lookup_Curve_HotSpot_Coef_Y: operation=rp_CS_MemAbsSet.Set_BsConst_Lookup_Curve_HotSpot_Coef_Y
            OA_rp_CS_MemAbsSet_Set_BsConst_Temp_Threshold_Hysteresis_Derating: operation=rp_CS_MemAbsSet.Set_BsConst_Temp_Threshold_Hysteresis_Derating
            OA_rp_CS_MemAbsSet_Set_BsConst_Derating_Backlight_Disable: operation=rp_CS_MemAbsSet.Set_BsConst_Derating_Backlight_Disable
            OA_rp_CS_MemAbsSet_Set_BsConst_Temperature_Sensor_Conv: operation=rp_CS_MemAbsSet.Set_BsConst_Temperature_Sensor_Conv
            OA_rp_CS_MemAbsSet_Set_BsConst_PCB_Temperature_Sensor_Conv: operation=rp_CS_MemAbsSet.Set_BsConst_PCB_Temperature_Sensor_Conv
            OA_rp_CS_MemAbsSet_Set_BsConst_Display_Illum_Max_Level: operation=rp_CS_MemAbsSet.Set_BsConst_Display_Illum_Max_Level
            OA_rp_CS_MemAbsSet_Set_BsConst_PWM_boost_bypass_duty: operation=rp_CS_MemAbsSet.Set_BsConst_PWM_boost_bypass_duty
            OA_rp_CS_MemAbsSet_Set_BsConst_BsConst_Illumination_ReservedByte: operation=rp_CS_MemAbsSet.Set_BsConst_BsConst_Illumination_ReservedByte
            OA_rp_CS_MemAbsSet_Set_BsConst_Compensation_Line_Slope_m_SafeCopy1: operation=rp_CS_MemAbsSet.Set_BsConst_Compensation_Line_Slope_m_SafeCopy1
            OA_rp_CS_MemAbsSet_Set_BsConst_Compensation_Line_Shift_b_SafeCopy1: operation=rp_CS_MemAbsSet.Set_BsConst_Compensation_Line_Shift_b_SafeCopy1
            OA_rp_CS_MemAbsSet_Set_BsConst_Lookup_Curve_HotSpot_Coef_X_SafeCopy1: operation=rp_CS_MemAbsSet.Set_BsConst_Lookup_Curve_HotSpot_Coef_X_SafeCopy1
            OA_rp_CS_MemAbsSet_Set_BsConst_Lookup_Curve_HotSpot_Coef_Y_SafeCopy1: operation=rp_CS_MemAbsSet.Set_BsConst_Lookup_Curve_HotSpot_Coef_Y_SafeCopy1
            OA_rp_CS_MemAbsSet_Set_BsConst_Temp_Threshold_Hysteresis_Derating_SafeCopy1: operation=rp_CS_MemAbsSet.Set_BsConst_Temp_Threshold_Hysteresis_Derating_SafeCopy1
            OA_rp_CS_MemAbsSet_Set_BsConst_Derating_Backlight_Disable_SafeCopy1: operation=rp_CS_MemAbsSet.Set_BsConst_Derating_Backlight_Disable_SafeCopy1
            OA_rp_CS_MemAbsSet_Set_BsConst_Temperature_Sensor_Conv_SafeCopy1: operation=rp_CS_MemAbsSet.Set_BsConst_Temperature_Sensor_Conv_SafeCopy1
            OA_rp_CS_MemAbsSet_Set_BsConst_PCB_Temperature_Sensor_Conv_SafeCopy1: operation=rp_CS_MemAbsSet.Set_BsConst_PCB_Temperature_Sensor_Conv_SafeCopy1
            OA_rp_CS_MemAbsSet_Set_BsConst_Display_Illum_Max_Level_SafeCopy1: operation=rp_CS_MemAbsSet.Set_BsConst_Display_Illum_Max_Level_SafeCopy1
            OA_rp_CS_MemAbsSet_Set_BsConst_PWM_boost_bypass_duty_SafeCopy1: operation=rp_CS_MemAbsSet.Set_BsConst_PWM_boost_bypass_duty_SafeCopy1
            OA_rp_CS_MemAbsSet_Set_BsConst_BsConst_Illumination_ReservedByte_SafeCopy1: operation=rp_CS_MemAbsSet.Set_BsConst_BsConst_Illumination_ReservedByte_SafeCopy1
            OA_rp_CS_MemAbsSet_Set_BsConst_Compensation_Line_Slope_m_SafeCopy2: operation=rp_CS_MemAbsSet.Set_BsConst_Compensation_Line_Slope_m_SafeCopy2
            OA_rp_CS_MemAbsSet_Set_BsConst_Compensation_Line_Shift_b_SafeCopy2: operation=rp_CS_MemAbsSet.Set_BsConst_Compensation_Line_Shift_b_SafeCopy2
            OA_rp_CS_MemAbsSet_Set_BsConst_Lookup_Curve_HotSpot_Coef_X_SafeCopy2: operation=rp_CS_MemAbsSet.Set_BsConst_Lookup_Curve_HotSpot_Coef_X_SafeCopy2
            OA_rp_CS_MemAbsSet_Set_BsConst_Lookup_Curve_HotSpot_Coef_Y_SafeCopy2: operation=rp_CS_MemAbsSet.Set_BsConst_Lookup_Curve_HotSpot_Coef_Y_SafeCopy2
            OA_rp_CS_MemAbsSet_Set_BsConst_Temp_Threshold_Hysteresis_Derating_SafeCopy2: operation=rp_CS_MemAbsSet.Set_BsConst_Temp_Threshold_Hysteresis_Derating_SafeCopy2
            OA_rp_CS_MemAbsSet_Set_BsConst_Derating_Backlight_Disable_SafeCopy2: operation=rp_CS_MemAbsSet.Set_BsConst_Derating_Backlight_Disable_SafeCopy2
            OA_rp_CS_MemAbsSet_Set_BsConst_Temperature_Sensor_Conv_SafeCopy2: operation=rp_CS_MemAbsSet.Set_BsConst_Temperature_Sensor_Conv_SafeCopy2
            OA_rp_CS_MemAbsSet_Set_BsConst_PCB_Temperature_Sensor_Conv_SafeCopy2: operation=rp_CS_MemAbsSet.Set_BsConst_PCB_Temperature_Sensor_Conv_SafeCopy2
            OA_rp_CS_MemAbsSet_Set_BsConst_Display_Illum_Max_Level_SafeCopy2: operation=rp_CS_MemAbsSet.Set_BsConst_Display_Illum_Max_Level_SafeCopy2
            OA_rp_CS_MemAbsSet_Set_BsConst_PWM_boost_bypass_duty_SafeCopy2: operation=rp_CS_MemAbsSet.Set_BsConst_PWM_boost_bypass_duty_SafeCopy2
            OA_rp_CS_MemAbsSet_Set_BsConst_BsConst_Illumination_ReservedByte_SafeCopy2: operation=rp_CS_MemAbsSet.Set_BsConst_BsConst_Illumination_ReservedByte_SafeCopy2
        DltExt_SendLogMessage
        DltExt_SetCounterToDefault
        DltExt_SetLogsToDefault
        DltExt_GetResetInfo
        DltExt_OnDreDLTMessageReadAckData
  swc implementation IMPL_DltExt: behavior=IB_DltExt
